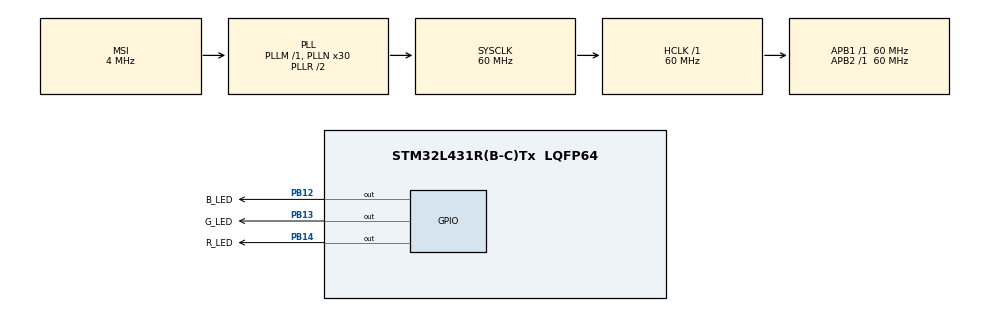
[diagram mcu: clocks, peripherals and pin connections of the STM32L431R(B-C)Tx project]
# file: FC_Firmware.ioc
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FREERTOS.Tasks01=RedLed,24,128,PrvRedLED,Default,NULL,Dynamic,NULL,NULL;GreenLed,8,128,PrvGreenLED,Default,NULL,Dynamic,NULL,NULL;BlueLed,8,128,PrvBlueLED,Default,NULL,Dynamic,NULL,NULL
FREERTOS.configUSE_IDLE_HOOK=1
FREERTOS.configUSE_NEWLIB_REENTRANT=1
Mcu.Family=STM32L4
Mcu.Name=STM32L431R(B-C)Tx
Mcu.Package=LQFP64
NVIC.PriorityGroup=NVIC_PRIORITYGROUP_4
NVIC.TIM1_UP_TIM16_IRQn=true\:15\:0\:false\:false\:true\:false\:false\:true\:true
NVIC.TimeBase=TIM1_UP_TIM16_IRQn
NVIC.TimeBaseIP=TIM1
PA13\ (JTMS-SWDIO).Mode=JTAG_4_pins
PA13\ (JTMS-SWDIO).Signal=SYS_JTMS-SWDIO
PA14\ (JTCK-SWCLK).Mode=JTAG_4_pins
PA14\ (JTCK-SWCLK).Signal=SYS_JTCK-SWCLK
PA15\ (JTDI).Mode=JTAG_4_pins
PA15\ (JTDI).Signal=SYS_JTDI
PB12.GPIO_Label=B_LED
PB12.Signal=GPIO_Output
PB13.GPIO_Label=G_LED
PB13.Signal=GPIO_Output
PB14.GPIO_Label=R_LED
PB14.Signal=GPIO_Output
PB3\ (JTDO-TRACESWO).Mode=JTAG_4_pins
PB3\ (JTDO-TRACESWO).Signal=SYS_JTDO-SWO
PH0-OSC_IN\ (PH0).Mode=HSE-External-Oscillator
PH0-OSC_IN\ (PH0).Signal=RCC_OSC_IN
PH1-OSC_OUT\ (PH1).Mode=HSE-External-Oscillator
PH1-OSC_OUT\ (PH1).Signal=RCC_OSC_OUT
ProjectManager.HeapSize=0x200
ProjectManager.StackSize=0x400
ProjectManager.TargetToolchain=STM32CubeIDE
RCC.ADCFreq_Value=16000000
RCC.AHBFreq_Value=60000000
RCC.APB1Freq_Value=60000000
RCC.APB1TimFreq_Value=60000000
RCC.APB2Freq_Value=60000000
RCC.APB2TimFreq_Value=60000000
RCC.CortexFreq_Value=60000000
RCC.HCLKFreq_Value=60000000
RCC.HSE_VALUE=8000000
RCC.HSI48_VALUE=48000000
RCC.HSI_VALUE=16000000
RCC.LSE_VALUE=32768
RCC.MSI_VALUE=4000000
RCC.PLLN=30
RCC.SYSCLKFreq_VALUE=60000000
RCC.SYSCLKSource=RCC_SYSCLKSOURCE_PLLCLK
RCC.VCOOutputFreq_Value=120000000
VP_FREERTOS_VS_CMSIS_V2.Mode=CMSIS_V2
VP_SYS_VS_tim1.Mode=TIM1
board=custom

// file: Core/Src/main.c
/* USER CODE BEGIN Header */
/**
  ******************************************************************************
  * @file           : main.c
  * @brief          : Main program body
  ******************************************************************************
  * @attention
  *
  * Copyright (c) 2023 STMicroelectronics.
  * All rights reserved.
  *
  * This software is licensed under terms that can be found in the LICENSE file
  * in the root directory of this software component.
  * If no LICENSE file comes with this software, it is provided AS-IS.
  *
  ******************************************************************************
  */
/* USER CODE END Header */
#include "main.h"
#include "cmsis_os.h"

/* Definitions for RedLed */
osThreadId_t RedLedHandle;
const osThreadAttr_t RedLed_attributes = {
  .name = "RedLed",
  .stack_size = 128 * 4,
  .priority = (osPriority_t) osPriorityNormal,
};
/* Definitions for GreenLed */
osThreadId_t GreenLedHandle;
const osThreadAttr_t GreenLed_attributes = {
  .name = "GreenLed",
  .stack_size = 128 * 4,
  .priority = (osPriority_t) osPriorityLow,
};
/* Definitions for BlueLed */
osThreadId_t BlueLedHandle;
const osThreadAttr_t BlueLed_attributes = {
  .name = "BlueLed",
  .stack_size = 128 * 4,
  .priority = (osPriority_t) osPriorityLow,
};

void SystemClock_Config(void);
static void MX_GPIO_Init(void);
void PrvRedLED(void *argument);
void PrvGreenLED(void *argument);
void PrvBlueLED(void *argument);

int main(void)
{

  /* MCU Configuration--------------------------------------------------------*/

  /* Reset of all peripherals, Initializes the Flash interface and the Systick. */
  HAL_Init();

  /* Configure the system clock */
  SystemClock_Config();

  /* Initialize all configured peripherals */
  MX_GPIO_Init();

  /* Init scheduler */
  osKernelInitialize();

  /* Create the thread(s) */
  /* creation of RedLed */
  RedLedHandle = osThreadNew(PrvRedLED, NULL, &RedLed_attributes);

  /* creation of GreenLed */
  GreenLedHandle = osThreadNew(PrvGreenLED, NULL, &GreenLed_attributes);

  /* creation of BlueLed */
  BlueLedHandle = osThreadNew(PrvBlueLED, NULL, &BlueLed_attributes);

  /* Start scheduler */
  osKernelStart();

  /* We should never get here as control is now taken by the scheduler */
  /* Infinite loop */
  while (1)
  {

  }
}

void SystemClock_Config(void)
{
  RCC_OscInitTypeDef RCC_OscInitStruct = {0};
  RCC_ClkInitTypeDef RCC_ClkInitStruct = {0};

  /** Configure the main internal regulator output voltage
  */
  if (HAL_PWREx_ControlVoltageScaling(PWR_REGULATOR_VOLTAGE_SCALE1) != HAL_OK)
  {
    Error_Handler();
  }

  /** Initializes the RCC Oscillators according to the specified parameters
  * in the RCC_OscInitTypeDef structure.
  */
  RCC_OscInitStruct.OscillatorType = RCC_OSCILLATORTYPE_MSI;
  RCC_OscInitStruct.MSIState = RCC_MSI_ON;
  RCC_OscInitStruct.MSICalibrationValue = 0;
  RCC_OscInitStruct.MSIClockRange = RCC_MSIRANGE_6;
  RCC_OscInitStruct.PLL.PLLState = RCC_PLL_ON;
  RCC_OscInitStruct.PLL.PLLSource = RCC_PLLSOURCE_MSI;
  RCC_OscInitStruct.PLL.PLLM = 1;
  RCC_OscInitStruct.PLL.PLLN = 30;
  RCC_OscInitStruct.PLL.PLLP = RCC_PLLP_DIV7;
  RCC_OscInitStruct.PLL.PLLQ = RCC_PLLQ_DIV2;
  RCC_OscInitStruct.PLL.PLLR = RCC_PLLR_DIV2;
  if (HAL_RCC_OscConfig(&RCC_OscInitStruct) != HAL_OK)
  {
    Error_Handler();
  }

  /** Initializes the CPU, AHB and APB buses clocks
  */
  RCC_ClkInitStruct.ClockType = RCC_CLOCKTYPE_HCLK|RCC_CLOCKTYPE_SYSCLK
                              |RCC_CLOCKTYPE_PCLK1|RCC_CLOCKTYPE_PCLK2;
  RCC_ClkInitStruct.SYSCLKSource = RCC_SYSCLKSOURCE_PLLCLK;
  RCC_ClkInitStruct.AHBCLKDivider = RCC_SYSCLK_DIV1;
  RCC_ClkInitStruct.APB1CLKDivider = RCC_HCLK_DIV1;
  RCC_ClkInitStruct.APB2CLKDivider = RCC_HCLK_DIV1;

  if (HAL_RCC_ClockConfig(&RCC_ClkInitStruct, FLASH_LATENCY_3) != HAL_OK)
  {
    Error_Handler();
  }
}

static void MX_GPIO_Init(void)
{
  GPIO_InitTypeDef GPIO_InitStruct = {0};

  /* GPIO Ports Clock Enable */
  __HAL_RCC_GPIOH_CLK_ENABLE();
  __HAL_RCC_GPIOB_CLK_ENABLE();
  __HAL_RCC_GPIOA_CLK_ENABLE();

  /*Configure GPIO pin Output Level */
  HAL_GPIO_WritePin(GPIOB, B_LED_Pin|G_LED_Pin|R_LED_Pin, GPIO_PIN_RESET);

  /*Configure GPIO pins : B_LED_Pin G_LED_Pin R_LED_Pin */
  GPIO_InitStruct.Pin = B_LED_Pin|G_LED_Pin|R_LED_Pin;
  GPIO_InitStruct.Mode = GPIO_MODE_OUTPUT_PP;
  GPIO_InitStruct.Pull = GPIO_NOPULL;
  GPIO_InitStruct.Speed = GPIO_SPEED_FREQ_LOW;
  HAL_GPIO_Init(GPIOB, &GPIO_InitStruct);

}

void PrvRedLED(void *argument)
{
  /* USER CODE BEGIN 5 */
	/* Infinite loop */
	for(;;)
	{
		HAL_GPIO_TogglePin(R_LED_GPIO_Port, R_LED_Pin);
		osDelay(500);
  }
  /* USER CODE END 5 */
}

void PrvGreenLED(void *argument)
{
  /* USER CODE BEGIN PrvGreenLED */
	/* Infinite loop */
	for(;;)
	{
		HAL_GPIO_TogglePin(G_LED_GPIO_Port, G_LED_Pin);
		osDelay(125);
	}
  /* USER CODE END PrvGreenLED */
}

void PrvBlueLED(void *argument)
{
  /* USER CODE BEGIN PrvBlueLED */
	/* Infinite loop */
	for(;;)
	{
		HAL_GPIO_TogglePin(B_LED_GPIO_Port, B_LED_Pin);
		osDelay(250);
	}
  /* USER CODE END PrvBlueLED */
}

void HAL_TIM_PeriodElapsedCallback(TIM_HandleTypeDef *htim)
{
  if (htim->Instance == TIM1) {
    HAL_IncTick();
  }
}

void Error_Handler(void)
{
  __disable_irq();
  while (1)
  {
  }
}
